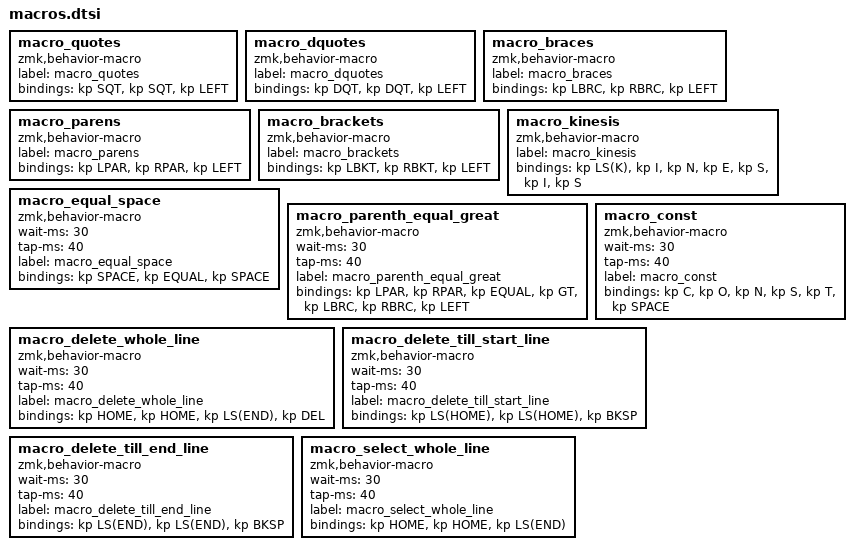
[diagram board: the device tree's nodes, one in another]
macro_quotes: macro_quotes{
compatible = "zmk,behavior-macro";
label = "macro_quotes";
#binding-cells = <0>;
bindings = <&kp SQT>, <&kp SQT>, <&kp LEFT>;
};
macro_dquotes: macro_dquotes{
compatible = "zmk,behavior-macro";
label = "macro_dquotes";
#binding-cells = <0>;
bindings = <&kp DQT>, <&kp DQT>, <&kp LEFT>;
};
macro_braces: macro_braces{
compatible = "zmk,behavior-macro";
label = "macro_braces";
#binding-cells = <0>;
bindings = <&kp LBRC>, <&kp RBRC>, <&kp LEFT>;
};
macro_parens: macro_parens{
compatible = "zmk,behavior-macro";
label = "macro_parens";
#binding-cells = <0>;
bindings = <&kp LPAR>, <&kp RPAR>, <&kp LEFT>;
};
macro_brackets: macro_brackets{
compatible = "zmk,behavior-macro";
label = "macro_brackets";
#binding-cells = <0>;
bindings = <&kp LBKT>, <&kp RBKT>, <&kp LEFT>;
};
macro_kinesis: macro_kinesis{
compatible = "zmk,behavior-macro";
label = "macro_kinesis";
#binding-cells = <0>;
bindings = <&kp LS(K)>, <&kp I>, <&kp N>, <&kp E>, <&kp S>, <&kp I>, <&kp S>;
};
// =  =  =  =  =  =
macro_equal_space: macro_equal_space{
compatible = "zmk,behavior-macro";
wait-ms = <30>;
tap-ms = <40>;
label = "macro_equal_space";
#binding-cells = <0>;
bindings = <&kp SPACE>, <&kp EQUAL>, <&kp SPACE>;
};
// ()=>{}
macro_parenth_equal_great: macro_parenth_equal_great{
compatible = "zmk,behavior-macro";
wait-ms = <30>;
tap-ms = <40>;
label = "macro_parenth_equal_great";
#binding-cells = <0>;
bindings = <&kp LPAR>, <&kp RPAR>,<&kp EQUAL>,<&kp GT>,<&kp LBRC>,<&kp RBRC>, <&kp LEFT>;
};
// const 
macro_const: macro_const{
compatible = "zmk,behavior-macro";
wait-ms = <30>;
tap-ms = <40>;
label = "macro_const";
#binding-cells = <0>;
bindings = <&kp C>, <&kp O>, <&kp N>, <&kp S>, <&kp T>, <&kp SPACE>;
};
macro_delete_whole_line: macro_delete_whole_line{
compatible = "zmk,behavior-macro";
wait-ms = <30>;
tap-ms = <40>;
label = "macro_delete_whole_line";
#binding-cells = <0>;
bindings = <&kp HOME>,<&kp HOME>, <&kp LS(END)>, <&kp DEL>;
};
macro_delete_till_start_line: macro_delete_till_start_line{
compatible = "zmk,behavior-macro";
wait-ms = <30>;
tap-ms = <40>;
label = "macro_delete_till_start_line";
#binding-cells = <0>;
bindings = <&kp LS(HOME)>, <&kp LS(HOME)>, <&kp BKSP>;
};
macro_delete_till_end_line: macro_delete_till_end_line{
compatible = "zmk,behavior-macro";
wait-ms = <30>;
tap-ms = <40>;
label = "macro_delete_till_end_line";
#binding-cells = <0>;
bindings = <&kp LS(END)>, <&kp LS(END)>, <&kp BKSP>;
};
macro_select_whole_line: macro_select_whole_line{
compatible = "zmk,behavior-macro";
wait-ms = <30>;
tap-ms = <40>;
label = "macro_select_whole_line";
#binding-cells = <0>;
bindings = <&kp HOME>,<&kp HOME>, <&kp LS(END)>;
};
/* 
macro_kinesis: macro_kinesis{
compatible = "zmk,behavior-macro";
label = "macro_kinesis";
#binding-cells = <0>;
bindings = <&kp LS(K)>, <&kp I>, <&kp N>, <&kp E>, <&kp S>, <&kp I>, <&kp S>;
};
*/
